# EFR32BG27C320F768IJ39 register map
Vendor: Silicon Labs; Series: EFR32; File version: B
Registers are 32-bit, read-write, reset 0x0 unless marked. A register's access mark holds for its fields unless they carry their own. Offsets are from the block's base; [hi:lo] are bit positions; {n}, {i} and the like mark numbered series; 'fields as' and 'values as' point back to an identical list.

## BURAM_NS — BURAM_NS Registers
Base 0x50080000
Same registers: BURAM_S 0x40080000
{0x0+4i} RET{i}_REG (i=0..31)
  [31:0] RETREG — Latch based Retention register

## BURTC_NS — BURTC_NS Registers
Base 0x50064000
Same registers: BURTC_S 0x40064000
0x00 IPVERSION ro
  [31:0] IPVERSION — IP Version ID
0x04 EN
  [0] EN — BURTC Enable
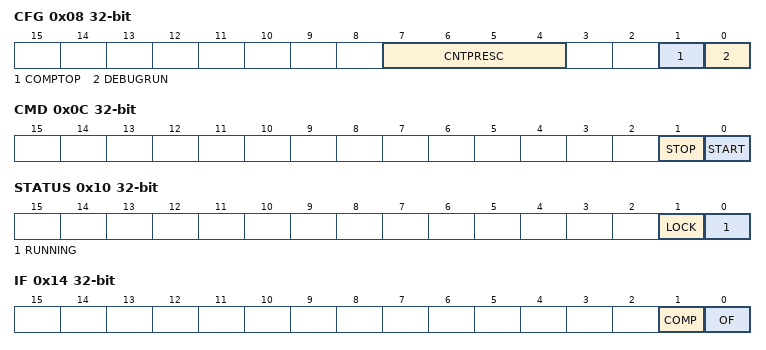
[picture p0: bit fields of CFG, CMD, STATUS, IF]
0x08 CFG
  [7:4] CNTPRESC — Counter prescaler value.
    0=DIV1 (CLK_CNT = (BURTC LF CLK)/1); 1=DIV2 (CLK_CNT = (BURTC LF CLK)/2); 2=DIV4 (CLK_CNT = (BURTC LF CLK)/4); 3=DIV8 (CLK_CNT = (BURTC LF CLK)/8); 4=DIV16 (CLK_CNT = (BURTC LF CLK)/16); 5=DIV32 (CLK_CNT = (BURTC LF CLK)/32); 6=DIV64 (CLK_CNT = (BURTC LF CLK)/64); 7=DIV128 (CLK_CNT = (BURTC LF CLK)/128); 8=DIV256 (CLK_CNT = (BURTC LF CLK)/256); 9=DIV512 (CLK_CNT = (BURTC LF CLK)/512); 10=DIV1024 (CLK_CNT = (BURTC LF CLK)/1024); 11=DIV2048 (CLK_CNT = (BURTC LF CLK)/2048); 12=DIV4096 (CLK_CNT = (BURTC LF CLK)/4096); 13=DIV8192 (CLK_CNT = (BURTC LF CLK)/8192); 14=DIV16384 (CLK_CNT = (BURTC LF CLK)/16384); 15=DIV32768 (CLK_CNT = (BURTC LF CLK)/32768)
  [1] COMPTOP — Compare Channel is Top Value
    0=DISABLE (The top value of the BURTC is 4294967295 (0xFFFFFFFF)); 1=ENABLE (The top value of the BURTC is given by COMP)
  [0] DEBUGRUN — Debug Mode Run Enable
    0=DISABLE (BURTC is frozen in debug mode); 1=ENABLE (BURTC is running in debug mode)
0x0C CMD wo
  [1] STOP — Stop BURTC counter
  [0] START — Start BURTC counter
0x10 STATUS ro
  [1] LOCK — Configuration Lock Status
    0=UNLOCKED (All BURTC lockable registers are unlocked.); 1=LOCKED (All BURTC lockable registers are locked.)
  [0] RUNNING — BURTC running status
0x14 IF
  [1] COMP — Compare Match Interrupt Flag
  [0] OF — Overflow Interrupt Flag
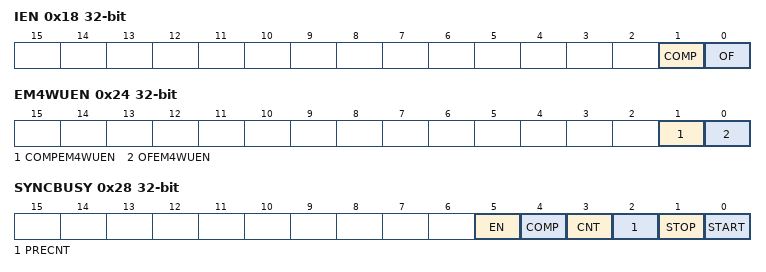
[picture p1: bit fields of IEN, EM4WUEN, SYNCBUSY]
0x18 IEN
  fields as IF
0x1C PRECNT
  [14:0] PRECNT — Pre-Counter Value
0x20 CNT
  [31:0] CNT — Counter Value
0x24 EM4WUEN
  [1] COMPEM4WUEN — Compare Match EM4 Wakeup Enable
  [0] OFEM4WUEN — Overflow EM4 Wakeup Enable
0x28 SYNCBUSY ro
  [5] EN — Sync busy for EN
  [4] COMP — Sync busy for COMP
  [3] CNT — Sync busy for CNT
  [2] PRECNT — Sync busy for PRECNT
  [1] STOP — Sync busy for STOP
  [0] START — Sync busy for START
0x2C LOCK wo reset 0xAEE8
  [15:0] LOCKKEY — Configuration Lock Key
    0xAEE8=UNLOCK (Write to unlock all BURTC lockable registers)
0x30 COMP
  [31:0] COMP — Compare Value

## DPLL0_NS — DPLL0_NS Registers
Base 0x5001C000
Same registers: DPLL0_S 0x4001C000
0x00 IPVERSION ro
  [31:0] IPVERSION — IP Version ID
0x04 EN
  [0] EN — Module Enable
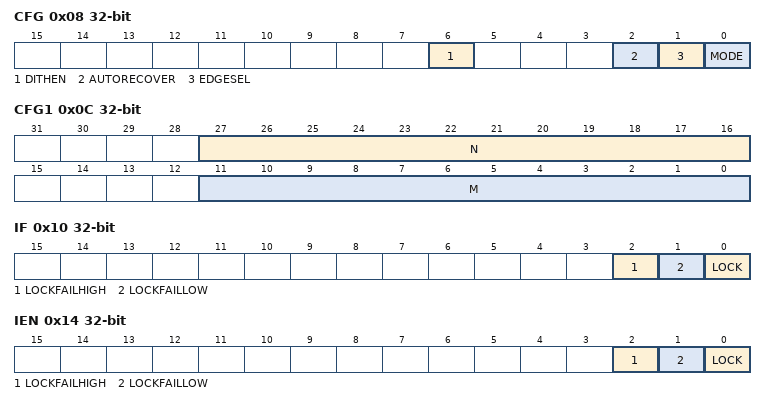
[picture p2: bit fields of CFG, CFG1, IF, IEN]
0x08 CFG
  [6] DITHEN — Dither Enable Control
  [2] AUTORECOVER — Automatic Recovery Control
  [1] EDGESEL — Reference Edge Select
  [0] MODE — Operating Mode Control
    0=FLL (Frequency Lock Mode); 1=PLL (Phase Lock Mode)
0x0C CFG1
  [27:16] N — Factor N
  [11:0] M — Factor M
0x10 IF
  [2] LOCKFAILHIGH — Lock Failure High Interrupt Flag
  [1] LOCKFAILLOW — Lock Failure Low Interrupt Flag
  [0] LOCK — Lock Interrupt Flag
0x14 IEN
  [2] LOCKFAILHIGH — LOCKFAILHIGH Interrupt Enable
  [1] LOCKFAILLOW — LOCKFAILLOW Interrupe Enable
  [0] LOCK — LOCK interrupt Enable
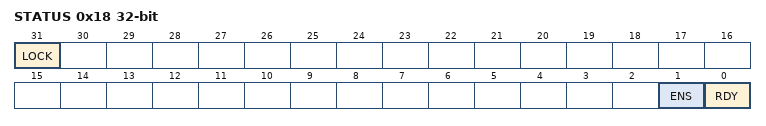
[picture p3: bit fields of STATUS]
0x18 STATUS ro
  [31] LOCK — Lock Status
    0=UNLOCKED (DPLL is unlocked); 1=LOCKED (DPLL is locked)
  [1] ENS — Enable Status
  [0] RDY — Ready Status
0x24 LOCK wo reset 0x7102
  [15:0] LOCKKEY
    0x7102=UNLOCK (Unlock code)

## ETAMPDET_NS — ETAMPDET_NS Registers
Base 0x500A4000
Same registers: ETAMPDET_S 0x400A4000
0x00 IPVERSION ro reset 0x2
  [31:0] IPVERSION — IP Version ID
0x04 EN
  [0] EN — ETAMPDET Enable
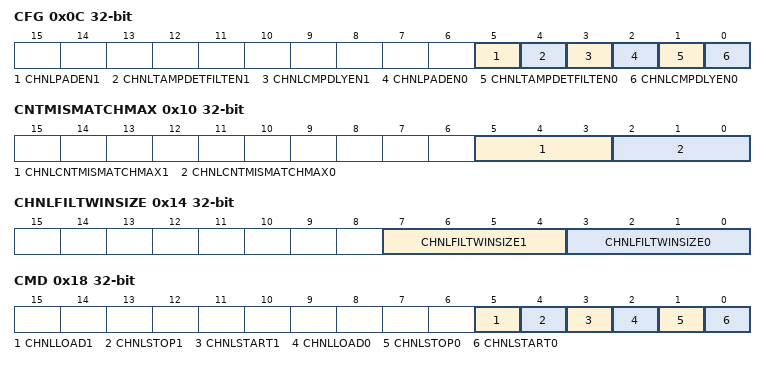
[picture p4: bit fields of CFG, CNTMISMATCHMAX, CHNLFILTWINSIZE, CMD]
0x0C CFG
  [5] CHNLPADEN1 — enable driving pad
    0=DISABLE (Disables channel 0 Tamper detect filtering feature); 1=ENABLE (Enables channel 0 Tamper detect filtering feature)
  [4] CHNLTAMPDETFILTEN1 — enable detect filtering
    0=DISABLE (Disables channel 1 Tamper detect filtering feature); 1=ENABLE (Enables channel 1 Tamper detect filtering feature)
  [3] CHNLCMPDLYEN1 — enable delay for comparison
    0=DISABLE (Disables 1 clock delay to the TX value used for comparison.); 1=ENABLE (Enables 1 clock delay to the TX value used for comparison.)
  [2] CHNLPADEN0 — enable driving pad
    values as CHNLPADEN1
  [1] CHNLTAMPDETFILTEN0 — enable detect filtering
    values as CHNLPADEN1
  [0] CHNLCMPDLYEN0 — enable delay for comparison
    0=Disables 1 clock delay to the TX value used for comparison; 1=Enables 1 clock delay to the TX value used for comparison
0x10 CNTMISMATCHMAX
  [5:3] CHNLCNTMISMATCHMAX1 — channel 1 filter counter threshold
    0=DetectFilterThreshold1 (Detect filter raise detect flag after seeing 1 event before reset counter expire); {v}=DetectFilterThreshold{v+1} (Detect filter raise detect flag after seeing {v+1} events before reset counter expire) (v=1..7)
  [2:0] CHNLCNTMISMATCHMAX0 — channel 0 filter counter threshold
    values as CHNLCNTMISMATCHMAX1
0x14 CHNLFILTWINSIZE
  [7:4] CHNLFILTWINSIZE1 — channel 1 Filter moving window size
    {v}=DetectFilterMovingWinSize{v+1} (Detect filter moving window size is {v+1}) (v=1..15)
  [3:0] CHNLFILTWINSIZE0 — channel 0 Filter moving window size
    values as CHNLFILTWINSIZE1
0x18 CMD wo
  [5] CHNLLOAD1 — Start channel 1 tamper detection
  [4] CHNLSTOP1 — Stop channel 1 tamper detection
  [3] CHNLSTART1 — Start channel 1 tamper detection
  [2] CHNLLOAD0 — Start channel 0 tamper detection
  [1] CHNLSTOP0 — Stop channel 0 tamper detection
  [0] CHNLSTART0 — Start channel 0 tamper detection
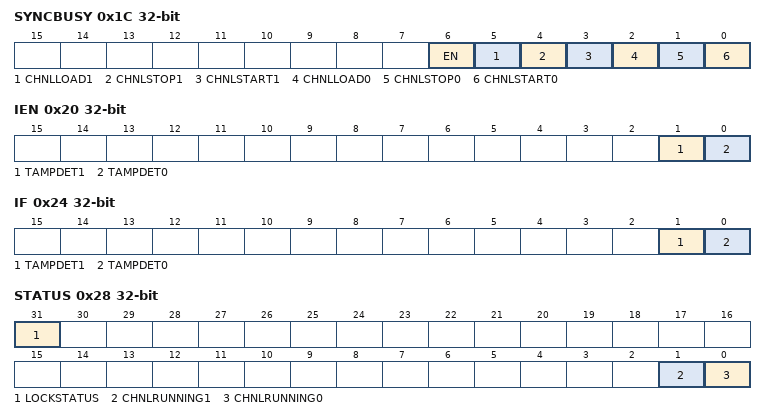
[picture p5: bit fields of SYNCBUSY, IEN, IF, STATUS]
0x1C SYNCBUSY ro
  [6] EN — Synchronizer busy status
  [5] CHNLLOAD1 — Synchronizer busy status
  [4] CHNLSTOP1 — Synchronizer busy status
  [3] CHNLSTART1 — Synchronizer busy status
  [2] CHNLLOAD0 — Synchronizer busy status
  [1] CHNLSTOP0 — Synchronizer busy status
  [0] CHNLSTART0 — Synchronizer busy status
0x20 IEN
  [1] TAMPDET1 — TAMPDET1 interrupt enable
  [0] TAMPDET0 — TAMPDET0 interrupt enable
0x24 IF
  [1] TAMPDET1 — Tamper1 Detect Flag
  [0] TAMPDET0 — Tamper0 Detect Flag
0x28 STATUS ro
  [31] LOCKSTATUS
    0=UNLOCKED (ETAMPDET registers are unlocked); 1=LOCKED (ETAMPDET registers are locked)
  [1] CHNLRUNNING1 — Channel1 Running Status
  [0] CHNLRUNNING0 — Channel0 Running Status
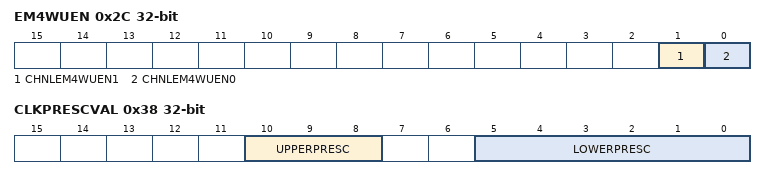
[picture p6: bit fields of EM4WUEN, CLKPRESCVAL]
0x2C EM4WUEN
  [1] CHNLEM4WUEN1 — Channel1 Tampdet EM4 Wakeup Enable
  [0] CHNLEM4WUEN0 — Channel0 Tampdet EM4 Wakeup Enable
0x30 CHNLSEEDVAL0
  [31:0] CHNLSEEDVAL0 — Channel 0 LFSR Seed Value
0x34 CHNLSEEDVAL1
  [31:0] CHNLSEEDVAL1 — Channel 1 LFSR Seed Value
0x38 CLKPRESCVAL — Finial dividing factor = RIPPLECNTUPPER * CNTLOWER
  [10:8] UPPERPRESC — Upper part of divider ripple counter
    0=Bypass (Ripple counter divider is bypassed); 1=DivideBy2; 2=DivideBy4; 3=DivideBy8; 4=DivideBy16; 5=DivideBy32; 6=DivideBy64
  [5:0] LOWERPRESC — Lower part of divider binary counter
    0=Bypass (Divider is bypassed); {v}=DivideBy{v+1} (v=1..63)
0x48 LOCK wo reset 0xAEE8
  [15:0] LOCKKEY — Configuration Lock Key
    0xAEE8=UNLOCK (Write to unlock all BURTC lockable registers)
